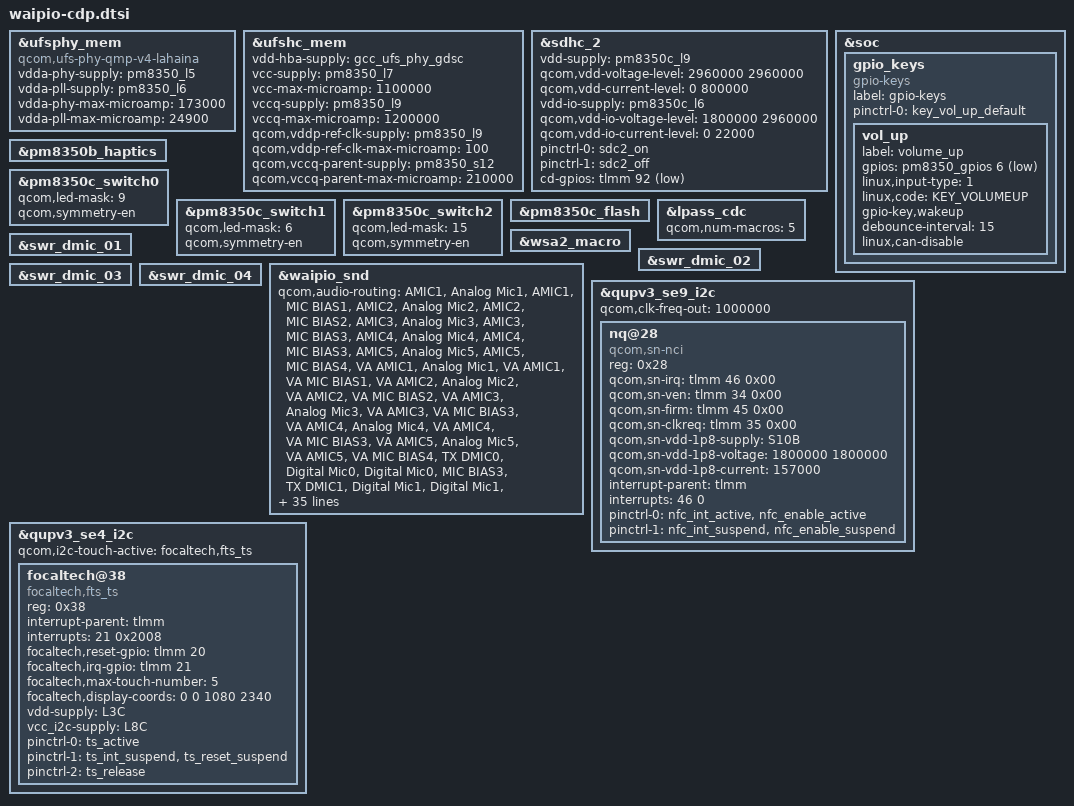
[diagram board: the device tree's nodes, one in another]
#include <dt-bindings/gpio/gpio.h>
#include <dt-bindings/input/input.h>

#include "waipio-pmic-overlay.dtsi"
#include "waipio-thermal-overlay.dtsi"
#include "waipio-audio-overlay.dtsi"

&ufsphy_mem {
	compatible = "qcom,ufs-phy-qmp-v4-lahaina";

	vdda-phy-supply = <&pm8350_l5>;
	vdda-pll-supply = <&pm8350_l6>;
	vdda-phy-max-microamp = <173000>;
	vdda-pll-max-microamp = <24900>;

	status = "ok";
};

&ufshc_mem {
	vdd-hba-supply = <&gcc_ufs_phy_gdsc>;

	vcc-supply = <&pm8350_l7>;
	vcc-max-microamp = <1100000>;

	vccq-supply = <&pm8350_l9>;
	vccq-max-microamp = <1200000>;

	qcom,vddp-ref-clk-supply = <&pm8350_l9>;
	qcom,vddp-ref-clk-max-microamp = <100>;

	qcom,vccq-parent-supply = <&pm8350_s12>;
	qcom,vccq-parent-max-microamp = <210000>;

	status = "ok";
};

&sdhc_2 {
	status = "ok";
	vdd-supply = <&pm8350c_l9>;
	qcom,vdd-voltage-level = <2960000 2960000>;
	qcom,vdd-current-level = <0 800000>;

	vdd-io-supply = <&pm8350c_l6>;
	qcom,vdd-io-voltage-level = <1800000 2960000>;
	qcom,vdd-io-current-level = <0 22000>;

	pinctrl-names = "default", "sleep";
	pinctrl-0 = <&sdc2_on>;
	pinctrl-1 = <&sdc2_off>;

	cd-gpios = <&tlmm 92 GPIO_ACTIVE_LOW>;
};

&soc {
	gpio_keys {
		compatible = "gpio-keys";
		label = "gpio-keys";

		pinctrl-names = "default";
		pinctrl-0 = <&key_vol_up_default>;

		vol_up {
			label = "volume_up";
			gpios = <&pm8350_gpios 6 GPIO_ACTIVE_LOW>;
			linux,input-type = <1>;
			linux,code = <KEY_VOLUMEUP>;
			gpio-key,wakeup;
			debounce-interval = <15>;
			linux,can-disable;
		};
	};
};

&pm8350b_haptics {
	status = "ok";
};

&pm8350c_switch0 {
	qcom,led-mask = <9>; /* Channels 1 & 4 */
	qcom,symmetry-en;
};

&pm8350c_switch1 {
	qcom,led-mask = <6>; /* Channels 2 & 3 */
	qcom,symmetry-en;
};

&pm8350c_switch2 {
	qcom,led-mask = <15>; /* All Channels */
	qcom,symmetry-en;
};

&pm8350c_flash {
	status = "ok";
};

&lpass_cdc {
	qcom,num-macros = <5>;
};

&wsa2_macro {
	status = "ok";
};

&swr_dmic_01 {
	status = "ok";
};

&swr_dmic_02 {
	status = "ok";
};

&swr_dmic_03 {
	status = "ok";
};

&swr_dmic_04 {
	status = "ok";
};

&waipio_snd {
	qcom,audio-routing =
		"AMIC1", "Analog Mic1",
		"AMIC1", "MIC BIAS1",
		"AMIC2", "Analog Mic2",
		"AMIC2", "MIC BIAS2",
		"AMIC3", "Analog Mic3",
		"AMIC3", "MIC BIAS3",
		"AMIC4", "Analog Mic4",
		"AMIC4", "MIC BIAS3",
		"AMIC5", "Analog Mic5",
		"AMIC5", "MIC BIAS4",
		"VA AMIC1", "Analog Mic1",
		"VA AMIC1", "VA MIC BIAS1",
		"VA AMIC2", "Analog Mic2",
		"VA AMIC2", "VA MIC BIAS2",
		"VA AMIC3", "Analog Mic3",
		"VA AMIC3", "VA MIC BIAS3",
		"VA AMIC4", "Analog Mic4",
		"VA AMIC4", "VA MIC BIAS3",
		"VA AMIC5", "Analog Mic5",
		"VA AMIC5", "VA MIC BIAS4",
		"TX DMIC0", "Digital Mic0",
		"Digital Mic0", "MIC BIAS3",
		"TX DMIC1", "Digital Mic1",
		"Digital Mic1", "MIC BIAS1",
		"TX DMIC2", "Digital Mic2",
		"Digital Mic2", "MIC BIAS1",
		"TX DMIC3", "Digital Mic3",
		"Digital Mic3", "MIC BIAS3",
		"IN1_HPHL", "HPHL_OUT",
		"IN2_HPHR", "HPHR_OUT",
		"IN3_AUX", "AUX_OUT",
		"HAP_IN", "PCM_OUT",
		"WSA SRC0_INP", "SRC0",
		"WSA2 SRC0_INP", "SRC0",
		"WSA_TX DEC0_INP", "TX DEC0 MUX",
		"WSA_TX DEC1_INP", "TX DEC1 MUX",
		"WSA2_TX DEC0_INP", "TX DEC0 MUX",
		"WSA2_TX DEC1_INP", "TX DEC1 MUX",
		"RX_TX DEC0_INP", "TX DEC0 MUX",
		"RX_TX DEC1_INP", "TX DEC1 MUX",
		"RX_TX DEC2_INP", "TX DEC2 MUX",
		"RX_TX DEC3_INP", "TX DEC3 MUX",
		"SpkrLeft IN", "WSA_SPK1 OUT",
		"SpkrRight IN", "WSA_SPK2 OUT",
		"Spkr2Left IN", "WSA2_SPK1 OUT",
		"Spkr2Right IN", "WSA2_SPK2 OUT",
		"TX SWR_INPUT", "WCD_TX_OUTPUT",
		"VA SWR_INPUT", "VA_SWR_CLK",
		"VA SWR_INPUT", "WCD_TX_OUTPUT",
		"VA_AIF1 CAP", "VA_SWR_CLK",
		"VA_AIF2 CAP", "VA_SWR_CLK",
		"VA_AIF3 CAP", "VA_SWR_CLK",
		"VA DMIC0", "Digital Mic0",
		"VA DMIC1", "Digital Mic1",
		"VA DMIC2", "Digital Mic2",
		"VA DMIC3", "Digital Mic3",
		"Digital Mic0", "VA MIC BIAS3",
		"Digital Mic1", "VA MIC BIAS1",
		"Digital Mic2", "VA MIC BIAS1",
		"Digital Mic3", "VA MIC BIAS3";
	qcom,cdc-dmic01-gpios = <&cdc_dmic01_gpios>;
	qcom,cdc-dmic23-gpios = <&cdc_dmic23_gpios>;
	qcom,cdc-dmic45-gpios = <&cdc_dmic45_gpios>;
	asoc-codec  = <&stub_codec>, <&lpass_cdc>,
		      <&wcd938x_codec>, <&swr_haptics>,
		      <&wsa883x_0221>, <&wsa883x_0222>,
		      <&wsa883x_2_0221>, <&wsa883x_2_0222>;
	asoc-codec-names = "msm-stub-codec.1", "lpass-cdc",
			   "wcd938x_codec", "swr-haptics",
			   "wsa-codec1", "wsa-codec2",
			   "wsa-codec3", "wsa-codec4";
	qcom,wsa-max-devs = <4>;
};

&qupv3_se9_i2c {
	status = "ok";
	qcom,clk-freq-out = <1000000>;
	#address-cells = <1>;
	#size-cells = <0>;
	nq@28 {
		compatible = "qcom,sn-nci";
		reg = <0x28>;
		qcom,sn-irq = <&tlmm 46 0x00>;
		qcom,sn-ven = <&tlmm 34 0x00>;
		qcom,sn-firm = <&tlmm 45 0x00>;
		qcom,sn-clkreq = <&tlmm 35 0x00>;
		qcom,sn-vdd-1p8-supply = <&S10B>;
		qcom,sn-vdd-1p8-voltage = <1800000 1800000>;
		qcom,sn-vdd-1p8-current = <157000>;
		interrupt-parent = <&tlmm>;
		interrupts = <46 0>;
		interrupt-names = "nfc_irq";
		pinctrl-names = "nfc_active", "nfc_suspend";
		pinctrl-0 = <&nfc_int_active &nfc_enable_active>;
		pinctrl-1 = <&nfc_int_suspend &nfc_enable_suspend>;
	};
};

&qupv3_se4_i2c {
	#address-cells = <1>;
	#size-cells = <0>;

	status = "ok";
	qcom,i2c-touch-active = "focaltech,fts_ts";

	focaltech@38 {
		compatible = "focaltech,fts_ts";
		reg = <0x38>;
		interrupt-parent = <&tlmm>;
		interrupts = <21 0x2008>;
		focaltech,reset-gpio = <&tlmm 20 0x00>;
		focaltech,irq-gpio = <&tlmm 21 0x2008>;
		focaltech,max-touch-number = <5>;
		focaltech,display-coords = <0 0 1080 2340>;

		vdd-supply = <&L3C>;
		vcc_i2c-supply = <&L8C>;

		pinctrl-names = "pmx_ts_active", "pmx_ts_suspend","pmx_ts_release";
		pinctrl-0 = <&ts_active>;
		pinctrl-1 = <&ts_int_suspend &ts_reset_suspend>;
		pinctrl-2 = <&ts_release>;
	};
};
